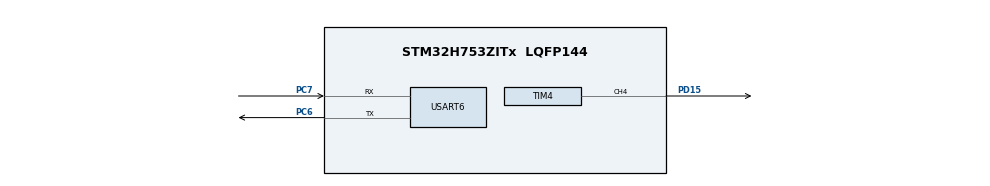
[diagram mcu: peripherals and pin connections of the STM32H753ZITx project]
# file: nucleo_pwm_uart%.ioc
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CORTEX_M7.CPU_DCache=Disabled
CORTEX_M7.CPU_ICache=Disabled
CORTEX_M7.MPU_Control=__NULL
CORTEX_M7.default_mode_Activation=1
Mcu.Family=STM32H7
Mcu.Name=STM32H753ZITx
Mcu.Package=LQFP144
NUCLEO-H753ZI.BUTTON=1
NUCLEO-H753ZI.Bsp_Common_DEMO=true
NUCLEO-H753ZI.LD1=true
NUCLEO-H753ZI.LD2=true
NUCLEO-H753ZI.LD3=true
NUCLEO-H753ZI.VCP=true
NVIC.EXTI15_10_IRQn=true\:0\:0\:false\:false\:true\:false\:true\:true
NVIC.PriorityGroup=NVIC_PRIORITYGROUP_4
PC14-OSC32_IN\ (OSC32_IN).Signal=RCC_OSC32_IN
PC15-OSC32_OUT\ (OSC32_OUT).Signal=RCC_OSC32_OUT
PC6.Mode=Asynchronous
PC6.Signal=USART6_TX
PC7.Mode=Asynchronous
PC7.Signal=USART6_RX
PD15.Signal=S_TIM4_CH4
PD8.Signal=USART3_TX
PD9.Signal=USART3_RX
PH0-OSC_IN\ (PH0).Signal=RCC_OSC_IN
PH1-OSC_OUT\ (PH1).Signal=RCC_OSC_OUT
ProjectManager.HeapSize=0x200
ProjectManager.StackSize=0x400
ProjectManager.TargetToolchain=STM32CubeIDE
RCC.ADCFreq_Value=129000000
RCC.APB1Freq_Value=64000000
RCC.APB2Freq_Value=64000000
RCC.APB3Freq_Value=64000000
RCC.APB4Freq_Value=64000000
RCC.CortexFreq_Value=64000000
RCC.DIVM1=1
RCC.DIVN1=24
RCC.DIVQ1=4
RCC.HCLKFreq_Value=64000000
RCC.HSE_VALUE=8000000
RCC.PLLFRACN=0
RCC.PWR_Regulator_Voltage_Scale=PWR_REGULATOR_VOLTAGE_SCALE2
RCC.SYSCLKFreq_VALUE=64000000
RCC.USBFreq_Value=384000000
SH.S_TIM4_CH4.0=TIM4_CH4,PWM Generation4 CH4
TIM4.AutoReloadPreload=TIM_AUTORELOAD_PRELOAD_ENABLE
TIM4.Channel-PWM\ Generation4\ CH4=TIM_CHANNEL_4
TIM4.Period=127
TIM4.Prescaler=63
USART6.VirtualMode-Asynchronous=VM_ASYNC
VP_MEMORYMAP_VS_MEMORYMAP.Mode=CurAppReg
VP_NUCLEO-H753ZI_VS_BSP_COMMON.Mode=COMMON
board=NUCLEO-H753ZI

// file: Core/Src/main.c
/* USER CODE BEGIN Header */
/**
  ******************************************************************************
  * @file           : main.c
  * @brief          : Main program body
  ******************************************************************************
  * @attention
  *
  * Copyright (c) 2026 STMicroelectronics.
  * All rights reserved.
  *
  * This software is licensed under terms that can be found in the LICENSE file
  * in the root directory of this software component.
  * If no LICENSE file comes with this software, it is provided AS-IS.
  *
  ******************************************************************************
  */
/* USER CODE END Header */
#include "main.h"
#include <stdio.h>
#include <string.h>

COM_InitTypeDef BspCOMInit;
__IO uint32_t BspButtonState = BUTTON_RELEASED;

TIM_HandleTypeDef htim4;

UART_HandleTypeDef huart6;

void SystemClock_Config(void);
static void MX_GPIO_Init(void);
static void MX_TIM4_Init(void);
static void MX_USART6_UART_Init(void);

/* USER CODE BEGIN 0 */
/* USER CODE BEGIN 0 */

// Redirect printf to UART6
/* USER CODE BEGIN 0 */

// Redirect printf to UART3 - Using weak attribute to override BSP definition
int __io_putchar(int ch) __attribute__((weak));

int __io_putchar(int ch)
{
  HAL_UART_Transmit(&huart6, (uint8_t *)&ch, 1, HAL_MAX_DELAY);
  return ch;
}

/* USER CODE END 0 */

/* USER CODE END 0 */

/* USER CODE END 0 */

int main(void)
{

  /* MCU Configuration--------------------------------------------------------*/

  /* Reset of all peripherals, Initializes the Flash interface and the Systick. */
  HAL_Init();

  /* Configure the system clock */
  SystemClock_Config();

  /* Initialize all configured peripherals */
  MX_GPIO_Init();
  MX_TIM4_Init();
  MX_USART6_UART_Init();
  /* USER CODE BEGIN 2 */
  // Start PWM on TIM4 Channel 4
  HAL_TIM_PWM_Start(&htim4, TIM_CHANNEL_4);

  // Send welcome message via UART
  printf("\r\n========================================\r\n");
  printf("STM32 PWM Control with UART Display\r\n");
  printf("========================================\r\n");
  printf("PWM Frequency: ~10 kHz\r\n");
  printf("Duty Cycle Range: 0%% to 100%%\r\n\r\n");

  HAL_Delay(1000);
  /* USER CODE END 2 */

  /* Initialize leds */
  BSP_LED_Init(LED_GREEN);
  BSP_LED_Init(LED_BLUE);
  BSP_LED_Init(LED_RED);

  /* Initialize USER push-button, will be used to trigger an interrupt each time it's pressed.*/
  BSP_PB_Init(BUTTON_USER, BUTTON_MODE_EXTI);

  /* Initialize COM1 port (115200, 8 bits (7-bit data + 1 stop bit), no parity */
  BspCOMInit.BaudRate   = 115200;
  BspCOMInit.WordLength = COM_WORDLENGTH_8B;
  BspCOMInit.StopBits   = COM_STOPBITS_1;
  BspCOMInit.Parity     = COM_PARITY_NONE;
  BspCOMInit.HwFlowCtl  = COM_HWCONTROL_NONE;
  if (BSP_COM_Init(COM1, &BspCOMInit) != BSP_ERROR_NONE)
  {
    Error_Handler();
  }

  /* USER CODE BEGIN BSP */

  /* -- Sample board code to send message over COM1 port ---- */
  printf("Welcome to STM32 world !\n\r");

  /* -- Sample board code to switch on leds ---- */
  BSP_LED_On(LED_GREEN);
  BSP_LED_On(LED_BLUE);
  BSP_LED_On(LED_RED);

  /* USER CODE END BSP */

  /* Infinite loop */
  /* USER CODE BEGIN WHILE */
  while (1)
  {

    /* -- Sample board code for User push-button in interrupt mode ---- */
	  for (int dutyCycle = 0; dutyCycle <= 100; dutyCycle++)
	    {
	      // Set PWM duty cycle (ARR=99, so dutyCycle value matches percentage)
	      __HAL_TIM_SET_COMPARE(&htim4, TIM_CHANNEL_4, dutyCycle);

	      // Display percentage via UART every 10%
	      if (dutyCycle % 10 == 0)
	      {
	        printf("LED Brightness: %3d%%  [", dutyCycle);

	        // Visual bar graph
	        int bars = dutyCycle / 10;
	        for (int i = 0; i < 10; i++)
	        {
	          if (i < bars)
	            printf("█");
	          else
	            printf("░");
	        }
	        printf("]\r\n");
	      }

	      HAL_Delay(50);  // 50ms delay per step
	    }

	    printf("\r\n--- Maximum Brightness Reached ---\r\n\r\n");
	    HAL_Delay(500);    /* USER CODE END WHILE */

	    // Fade OUT: 100% to 0% duty cycle
	     for (int dutyCycle = 100; dutyCycle >= 0; dutyCycle--)
	     {
	       // Set PWM duty cycle
	       __HAL_TIM_SET_COMPARE(&htim4, TIM_CHANNEL_4, dutyCycle);

	       // Display percentage via UART every 10%
	       if (dutyCycle % 10 == 0)
	       {
	         printf("LED Brightness: %3d%%  [", dutyCycle);

	         // Visual bar graph
	         int bars = dutyCycle / 10;
	         for (int i = 0; i < 10; i++)
	         {
	           if (i < bars)
	             printf("█");
	           else
	             printf("░");
	         }
	         printf("]\r\n");
	       }

	       HAL_Delay(50);
	     }

	     printf("\r\n--- Minimum Brightness Reached ---\r\n\r\n");
	     HAL_Delay(500);

  }
}

void SystemClock_Config(void)
{
  RCC_OscInitTypeDef RCC_OscInitStruct = {0};
  RCC_ClkInitTypeDef RCC_ClkInitStruct = {0};

  /** Supply configuration update enable
  */
  HAL_PWREx_ConfigSupply(PWR_LDO_SUPPLY);

  /** Configure the main internal regulator output voltage
  */
  __HAL_PWR_VOLTAGESCALING_CONFIG(PWR_REGULATOR_VOLTAGE_SCALE2);

  while(!__HAL_PWR_GET_FLAG(PWR_FLAG_VOSRDY)) {}

  /** Initializes the RCC Oscillators according to the specified parameters
  * in the RCC_OscInitTypeDef structure.
  */
  RCC_OscInitStruct.OscillatorType = RCC_OSCILLATORTYPE_HSI;
  RCC_OscInitStruct.HSIState = RCC_HSI_DIV1;
  RCC_OscInitStruct.HSICalibrationValue = RCC_HSICALIBRATION_DEFAULT;
  RCC_OscInitStruct.PLL.PLLState = RCC_PLL_NONE;
  if (HAL_RCC_OscConfig(&RCC_OscInitStruct) != HAL_OK)
  {
    Error_Handler();
  }

  /** Initializes the CPU, AHB and APB buses clocks
  */
  RCC_ClkInitStruct.ClockType = RCC_CLOCKTYPE_HCLK|RCC_CLOCKTYPE_SYSCLK
                              |RCC_CLOCKTYPE_PCLK1|RCC_CLOCKTYPE_PCLK2
                              |RCC_CLOCKTYPE_D3PCLK1|RCC_CLOCKTYPE_D1PCLK1;
  RCC_ClkInitStruct.SYSCLKSource = RCC_SYSCLKSOURCE_HSI;
  RCC_ClkInitStruct.SYSCLKDivider = RCC_SYSCLK_DIV1;
  RCC_ClkInitStruct.AHBCLKDivider = RCC_HCLK_DIV1;
  RCC_ClkInitStruct.APB3CLKDivider = RCC_APB3_DIV1;
  RCC_ClkInitStruct.APB1CLKDivider = RCC_APB1_DIV1;
  RCC_ClkInitStruct.APB2CLKDivider = RCC_APB2_DIV1;
  RCC_ClkInitStruct.APB4CLKDivider = RCC_APB4_DIV1;

  if (HAL_RCC_ClockConfig(&RCC_ClkInitStruct, FLASH_LATENCY_1) != HAL_OK)
  {
    Error_Handler();
  }
}

static void MX_TIM4_Init(void)
{

  TIM_MasterConfigTypeDef sMasterConfig = {0};
  TIM_OC_InitTypeDef sConfigOC = {0};

  htim4.Instance = TIM4;
  htim4.Init.Prescaler = 63;
  htim4.Init.CounterMode = TIM_COUNTERMODE_UP;
  htim4.Init.Period = 127;
  htim4.Init.ClockDivision = TIM_CLOCKDIVISION_DIV1;
  htim4.Init.AutoReloadPreload = TIM_AUTORELOAD_PRELOAD_ENABLE;
  if (HAL_TIM_PWM_Init(&htim4) != HAL_OK)
  {
    Error_Handler();
  }
  sMasterConfig.MasterOutputTrigger = TIM_TRGO_RESET;
  sMasterConfig.MasterSlaveMode = TIM_MASTERSLAVEMODE_DISABLE;
  if (HAL_TIMEx_MasterConfigSynchronization(&htim4, &sMasterConfig) != HAL_OK)
  {
    Error_Handler();
  }
  sConfigOC.OCMode = TIM_OCMODE_PWM1;
  sConfigOC.Pulse = 0;
  sConfigOC.OCPolarity = TIM_OCPOLARITY_HIGH;
  sConfigOC.OCFastMode = TIM_OCFAST_DISABLE;
  if (HAL_TIM_PWM_ConfigChannel(&htim4, &sConfigOC, TIM_CHANNEL_4) != HAL_OK)
  {
    Error_Handler();
  }
  HAL_TIM_MspPostInit(&htim4);

}

static void MX_USART6_UART_Init(void)
{

  huart6.Instance = USART6;
  huart6.Init.BaudRate = 115200;
  huart6.Init.WordLength = UART_WORDLENGTH_8B;
  huart6.Init.StopBits = UART_STOPBITS_1;
  huart6.Init.Parity = UART_PARITY_NONE;
  huart6.Init.Mode = UART_MODE_TX_RX;
  huart6.Init.HwFlowCtl = UART_HWCONTROL_NONE;
  huart6.Init.OverSampling = UART_OVERSAMPLING_16;
  huart6.Init.OneBitSampling = UART_ONE_BIT_SAMPLE_DISABLE;
  huart6.Init.ClockPrescaler = UART_PRESCALER_DIV1;
  huart6.AdvancedInit.AdvFeatureInit = UART_ADVFEATURE_NO_INIT;
  if (HAL_UART_Init(&huart6) != HAL_OK)
  {
    Error_Handler();
  }
  if (HAL_UARTEx_SetTxFifoThreshold(&huart6, UART_TXFIFO_THRESHOLD_1_8) != HAL_OK)
  {
    Error_Handler();
  }
  if (HAL_UARTEx_SetRxFifoThreshold(&huart6, UART_RXFIFO_THRESHOLD_1_8) != HAL_OK)
  {
    Error_Handler();
  }
  if (HAL_UARTEx_DisableFifoMode(&huart6) != HAL_OK)
  {
    Error_Handler();
  }

}

static void MX_GPIO_Init(void)
{

  /* GPIO Ports Clock Enable */
  __HAL_RCC_GPIOC_CLK_ENABLE();
  __HAL_RCC_GPIOH_CLK_ENABLE();
  __HAL_RCC_GPIOD_CLK_ENABLE();

}

/**
  * @brief BSP Push Button callback
  * @param Button Specifies the pressed button
  * @retval None
  */
void BSP_PB_Callback(Button_TypeDef Button)
{
  if (Button == BUTTON_USER)
  {
    BspButtonState = BUTTON_PRESSED;
  }
}

void Error_Handler(void)
{
  __disable_irq();
  while (1)
  {
  }
}
